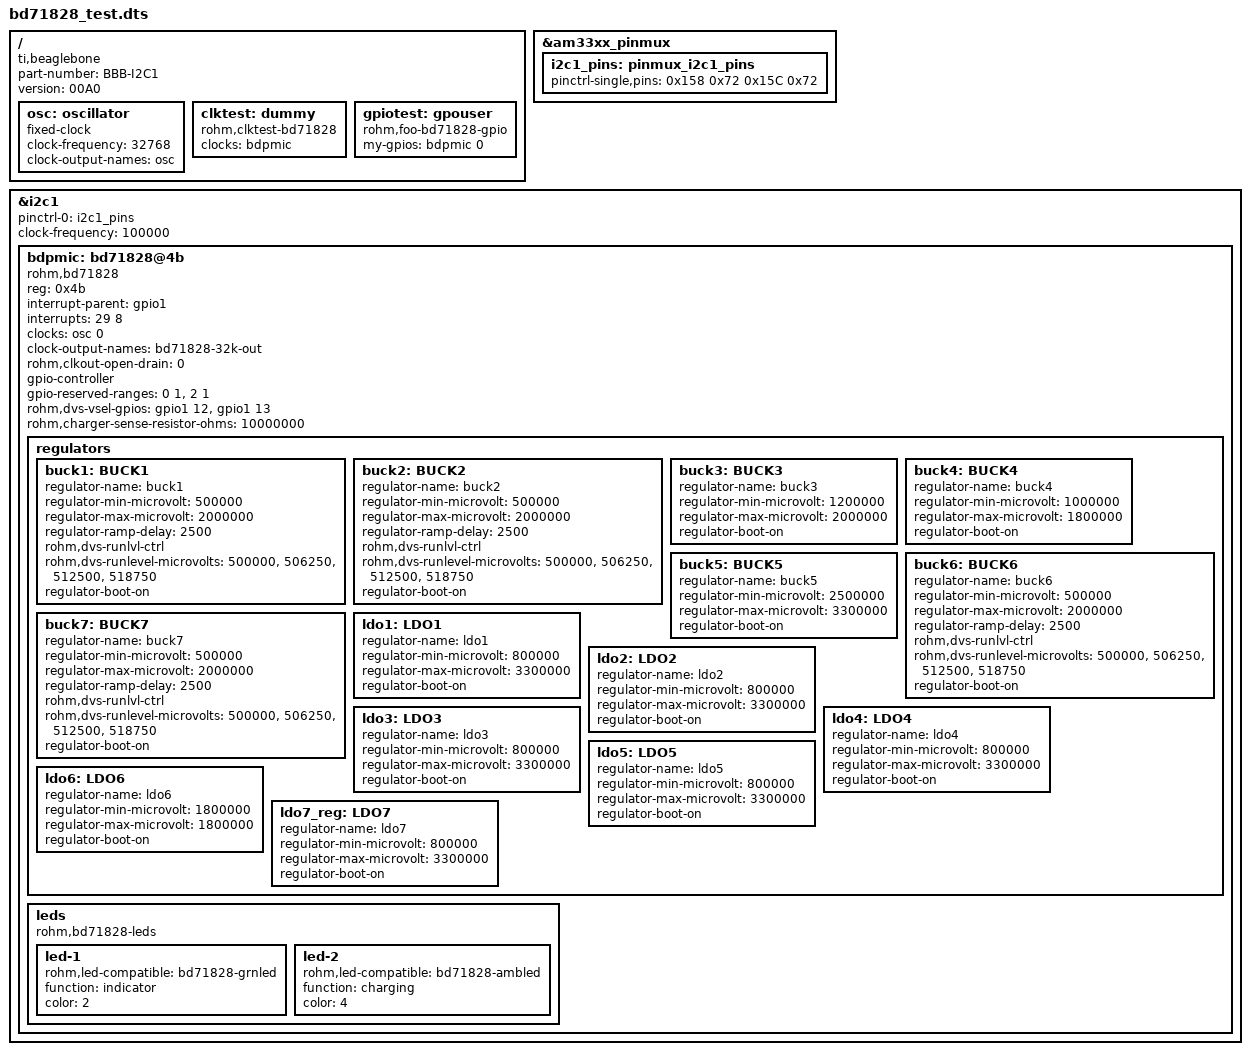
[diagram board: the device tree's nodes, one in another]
/dts-v1/;
/plugin/;

/{ /* this is our device tree overlay root node */

	compatible = "ti,beaglebone", "ti,beaglebone-black";
	part-number = "BBB-I2C1"; // you can choose any name here but it should be memorable
 	version = "00A0";

	fragment@0 {
		target = <&am33xx_pinmux>; // this is a link to an already defined node in the device tree, so that node is overlayed with our modification

		__overlay__ {
			i2c1_pins: pinmux_i2c1_pins {
				pinctrl-single,pins = <
				/* 0x158 - pin 17.
				   0x15C - pin 18
					0x72:
					b[2:0] = 2 => mux mode 2 (i2c1 p17/p18,SCL/SDA)
					b[3] = 0 => pullup/pulldown enabled
					b[4] = 1 => pull-up, not pull down
					b[5] = 1 => receiver active
					b[6] = 1 => slew control slow
				*/
          			0x158 0x72 /* spi0_d1.i2c1_sda */ 
          			0x15C 0x72 /* spi0_cs0.i2c1_sdl */
/*				0xA4 0x7    */ /* pin 46, GPIO 2_7 mode 7 */
/*				0xA0 0x7    */ /* pin 45, GPIO 2_6 mode 7 */
/*				0x0c 0x7    */ /* pin 3, GPIO 1_6 mode 7 */
/*				0x10 0x7    */ /* pin 4, GPIO 1_7 mode 7 */
        			>;
			};
		};
	};
	fragment@1 {
		target-path = "/";
		__overlay__ {
			/* external oscillator */
			osc: oscillator {
				compatible = "fixed-clock";
				#clock-cells = <1>;
				clock-frequency  = <32768>;
				clock-output-names = "osc";
			};
		};
	};

	fragment@2 {
		target = <&i2c1>;

		__overlay__ {
			pinctrl-0 = <&i2c1_pins>;
			clock-frequency = <100000>;
			status = "okay";



			bdpmic: bd71828@4b {
				compatible = "rohm,bd71828";
				reg = <0x4b>;
				/* Let's try using GPIO1_29 as irq pin */
				interrupt-parent = <&gpio1>;
//				/* GPIO 1_29 - (connector 8, pin 26) for irq */
/*				interrupts = <29 GPIO_ACTIVE_LOW>; */
				interrupts = <29 8>;
				clocks = <&osc 0>;
				#clock-cells = <0>;
				clock-output-names = "bd71828-32k-out";
				rohm,clkout-open-drain = <0>;
				#gpio-cells = <2>;
				gpio-controller;
				/* With default OTP the GPIO 1 is used for DVS0
				   input (not usable as GPO) and GPIO 3 is used
				   for DVS1 input. GPIO 2 can be used for GPO
				   and is by default connected to EPDEN. Let's
				   exclude GPIO 1 and 3 from use */
/*				ngpios = <4>; */
				gpio-reserved-ranges = <0 1>, <2 1>;
				rohm,dvs-vsel-gpios = <&gpio1 12 0>,
						      <&gpio1 13 0>;
				/* 10M RSENS resistor */ 
				rohm,charger-sense-resistor-ohms = <10000000>;

				regulators {
					buck1: BUCK1 {
						regulator-name = "buck1";
						regulator-min-microvolt = <500000>;
						regulator-max-microvolt = <2000000>;
						regulator-ramp-delay = <2500>;
						rohm,dvs-runlvl-ctrl;
						rohm,dvs-runlevel-microvolts =
								<500000>,
								<506250>,
								<512500>,
								<518750>;
						regulator-boot-on;
					};
					buck2: BUCK2 {
						regulator-name = "buck2";
						regulator-min-microvolt = <500000>;
						regulator-max-microvolt = <2000000>;
						regulator-ramp-delay = <2500>;
						rohm,dvs-runlvl-ctrl;
						rohm,dvs-runlevel-microvolts =
								<500000>,
								<506250>,
								<512500>,
								<518750>;
						regulator-boot-on;
					};
					buck3: BUCK3 {
						regulator-name = "buck3";
						regulator-min-microvolt = <1200000>;
						regulator-max-microvolt = <2000000>;
						regulator-boot-on;
					};
					buck4: BUCK4 {
						regulator-name = "buck4";
						regulator-min-microvolt = <1000000>;
						regulator-max-microvolt = <1800000>;
						regulator-boot-on;
					};
					buck5: BUCK5 {
						regulator-name = "buck5";
						regulator-min-microvolt = <2500000>;
						regulator-max-microvolt = <3300000>;
						regulator-boot-on;
					};
					buck6: BUCK6 {
						regulator-name = "buck6";
						regulator-min-microvolt = <500000>;
						regulator-max-microvolt = <2000000>;
						regulator-ramp-delay = <2500>;
						rohm,dvs-runlvl-ctrl;
						rohm,dvs-runlevel-microvolts =
								<500000>,
								<506250>,
								<512500>,
								<518750>;
						regulator-boot-on;
					};
					buck7: BUCK7 {
						regulator-name = "buck7";
						regulator-min-microvolt = <500000>;
						regulator-max-microvolt = <2000000>;
						regulator-ramp-delay = <2500>;
						rohm,dvs-runlvl-ctrl;
						rohm,dvs-runlevel-microvolts =
								<500000>,
								<506250>,
								<512500>,
								<518750>;
						regulator-boot-on;
					};
					ldo1: LDO1 {
						regulator-name = "ldo1";
						regulator-min-microvolt = <800000>;
						regulator-max-microvolt = <3300000>;
						regulator-boot-on;
					};
					ldo2: LDO2 {
						regulator-name = "ldo2";
						regulator-min-microvolt = <800000>;
						regulator-max-microvolt = <3300000>;
						regulator-boot-on;
					};
					ldo3: LDO3 {
						regulator-name = "ldo3";
						regulator-min-microvolt = <800000>;
						regulator-max-microvolt = <3300000>;
						regulator-boot-on;
					};
					ldo4: LDO4 {
						regulator-name = "ldo4";
						regulator-min-microvolt = <800000>;
						regulator-max-microvolt = <3300000>;
						regulator-boot-on;
					};
					ldo5: LDO5 {
						regulator-name = "ldo5";
						regulator-min-microvolt = <800000>;
						regulator-max-microvolt = <3300000>;
						regulator-boot-on;
					};
					ldo6: LDO6 {
						regulator-name = "ldo6";
						regulator-min-microvolt = <1800000>;
						regulator-max-microvolt = <1800000>;
						regulator-boot-on;
					};
					ldo7_reg: LDO7 {
						regulator-name = "ldo7";
						regulator-min-microvolt = <800000>;
						regulator-max-microvolt = <3300000>;
						regulator-boot-on;
					};
				};
				leds {
					compatible = "rohm,bd71828-leds";
					led-1 {
						rohm,led-compatible = "bd71828-grnled";
						function = "indicator";
						color = <2>;
					};
					led-2 {
						rohm,led-compatible = "bd71828-ambled";
						function = "charging";
						color = <4>;
					};
				};
			};
		};
	};

	fragment@3 {
		target-path = "/";
		__overlay__ {
			clktest: dummy {
				compatible = "rohm,clktest-bd71828";
				clocks = <&bdpmic>;
				clock-names = "foo-in";
			};
			gpiotest: gpouser {
				compatible = "rohm,foo-bd71828-gpio";
				my-gpios = <&bdpmic 0 0>;
			};
		};
	};
}; /* root node end */
